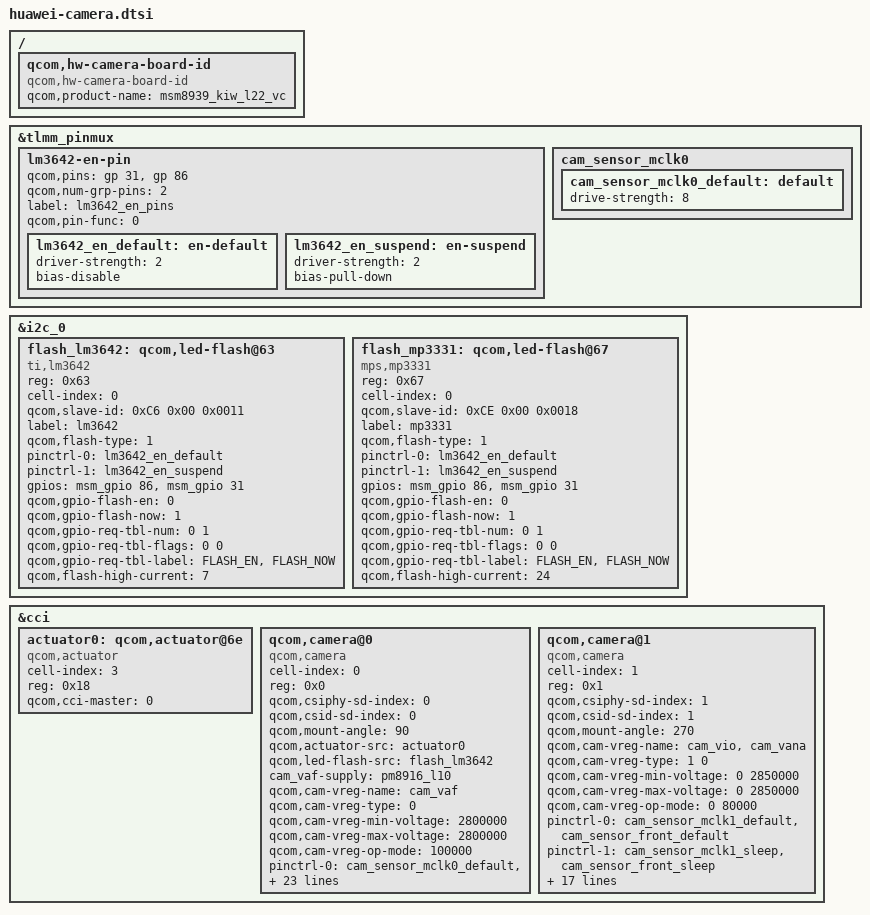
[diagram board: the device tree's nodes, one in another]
/*
 * Copyright (c) 2014, The Linux Foundation. All rights reserved.
 *
 * This program is free software; you can redistribute it and/or modify
 * it under the terms of the GNU General Public License version 2 and
 * only version 2 as published by the Free Software Foundation.
 *
 * This program is distributed in the hope that it will be useful,
 * but WITHOUT ANY WARRANTY; without even the implied warranty of
 * MERCHANTABILITY or FITNESS FOR A PARTICULAR PURPOSE.  See the
 * GNU General Public License for more details.
 */
&tlmm_pinmux {
	lm3642-en-pin {
		qcom,pins = <&gp 31>, <&gp 86>;
		qcom,num-grp-pins = <2>;
		label = "lm3642_en_pins";
		qcom,pin-func = <0>;

		lm3642_en_default: en-default {
			driver-strength = <2>;
			bias-disable;
		};
		lm3642_en_suspend: en-suspend {
			driver-strength = <2>;
			bias-pull-down;
		};
	};
	cam_sensor_mclk0 {
		cam_sensor_mclk0_default: default {
			drive-strength = <8>; /* 8 MA */
		};
	};
};

&i2c_0 { /* BLSP1 QUP2 */
	flash_lm3642:qcom,led-flash@63 {
		reg = <0x63>;
		cell-index = <0>;
		qcom,slave-id = <0xC6 0x00 0x0011>;
		compatible = "ti,lm3642";
		label = "lm3642";
		qcom,flash-type = <1>;
		pinctrl-names = "cam_flash_default","cam_flash_suspend";
		pinctrl-0 = <&lm3642_en_default>;
		pinctrl-1 = <&lm3642_en_suspend>;
		gpios = <&msm_gpio 86 0>,
			<&msm_gpio 31 0>;
		qcom,gpio-flash-en = <0>;
		qcom,gpio-flash-now = <1>;
		qcom,gpio-req-tbl-num = <0 1>;
		qcom,gpio-req-tbl-flags = <0 0>;
		qcom,gpio-req-tbl-label = "FLASH_EN",
			"FLASH_NOW";

		qcom,flash-high-current = <7>;/* 750mA */
	};
	flash_mp3331:qcom,led-flash@67 {
		reg = <0x67>;
		cell-index = <0>;
		qcom,slave-id = <0xCE 0x00 0x0018>;
		compatible = "mps,mp3331";
		label = "mp3331";
		qcom,flash-type = <1>;
		pinctrl-names = "cam_flash_default","cam_flash_suspend";
		pinctrl-0 = <&lm3642_en_default>;
		pinctrl-1 = <&lm3642_en_suspend>;
		gpios = <&msm_gpio 86 0>,
			<&msm_gpio 31 0>;
		qcom,gpio-flash-en = <0>;
		qcom,gpio-flash-now = <1>;
		qcom,gpio-req-tbl-num = <0 1>;
		qcom,gpio-req-tbl-flags = <0 0>;
		qcom,gpio-req-tbl-label = "FLASH_EN",
			"FLASH_NOW";

		qcom,flash-high-current = <24>;/* 750mA */
	};
};

/ {
    qcom,hw-camera-board-id {
		compatible = "qcom,hw-camera-board-id";
		qcom,product-name = "msm8939_kiw_l22_vc";
	};
};

&cci {
	actuator0: qcom,actuator@6e {
		cell-index = <3>;
		reg = <0x18>;
		compatible = "qcom,actuator";
		qcom,cci-master = <0>;
	};

	qcom,camera@0 {
		cell-index = <0>;
		compatible = "qcom,camera";
		reg = <0x0>;
		qcom,csiphy-sd-index = <0>;
		qcom,csid-sd-index = <0>;
		qcom,mount-angle = <90>;
		qcom,actuator-src = <&actuator0>;
		qcom,led-flash-src = <&flash_lm3642>;
		cam_vaf-supply = <&pm8916_l10>;
		qcom,cam-vreg-name = "cam_vaf";
		qcom,cam-vreg-type = <0>;
		qcom,cam-vreg-min-voltage = <2800000>;
		qcom,cam-vreg-max-voltage = <2800000>;
		qcom,cam-vreg-op-mode = <100000>;
		pinctrl-names = "cam_default", "cam_suspend";
		pinctrl-0 = <&cam_sensor_mclk0_default &cam_sensor_rear_default>;
		pinctrl-1 = <&cam_sensor_mclk0_sleep &cam_sensor_rear_sleep>;
		gpios = <&msm_gpio 26 0>,
				<&msm_gpio 35 0>,
				<&msm_gpio 121 0>,//core vreg
				<&msm_gpio 110 0>,
				<&msm_gpio 114 0>,
				<&msm_gpio 120 0>,
				<&msm_gpio 105 0>,
				<&msm_gpio 51 0>;
		qcom,gpio-reset = <1>;
		qcom,gpio-vdig = <2>;
		qcom,gpio-vana = <3>;
		qcom,gpio-vio = <4>;
		qcom,gpio-af-pwdm = <5>;
		qcom,gpio-cam-dvdd-sel = <6>;
		qcom,gpio-cam-id = <7>;
		qcom,gpio-req-tbl-num = <0 1 2 3 4 5 6 7>;
		qcom,gpio-req-tbl-flags = <1 0 0 0 0 0 0 1>;
		qcom,gpio-req-tbl-label = "CAMIF_MCLK",
				"CAM_RESET1",
				"CAM_VDIG",
				"CAM_VANA",
				"CAM_VIO",
				"CAM_AF_PWDM",
				"CAM_DVDD_SEL",
				"CAM_CAM_ID";
		qcom,sensor-position = <0>;
		qcom,sensor-mode = <0>;
		qcom,cci-master = <0>;
		status = "ok";
		clocks = <&clock_gcc clk_mclk0_clk_src>,
				<&clock_gcc clk_gcc_camss_mclk0_clk>;
		clock-names = "cam_src_clk", "cam_clk";
	};

	qcom,camera@1 {
		cell-index = <1>;
		compatible = "qcom,camera";
		reg = <0x1>;
		qcom,csiphy-sd-index = <1>;
		qcom,csid-sd-index = <1>;
		qcom,mount-angle = <270>;
		qcom,cam-vreg-name = "cam_vio", "cam_vana";
		qcom,cam-vreg-type = <1 0>;
		qcom,cam-vreg-min-voltage = <0 2850000>;
		qcom,cam-vreg-max-voltage = <0 2850000>;
		qcom,cam-vreg-op-mode = <0 80000>;
		pinctrl-names = "cam_default", "cam_suspend";
		pinctrl-0 = <&cam_sensor_mclk1_default &cam_sensor_front_default>;
		pinctrl-1 = <&cam_sensor_mclk1_sleep &cam_sensor_front_sleep>;
		gpios = <&msm_gpio 27 0>,
				<&msm_gpio 28 0>,
				<&msm_gpio 33 0>,
				<&msm_gpio 114 0>,
				<&msm_gpio 110 0>,
				<&msm_gpio 52 0>;
		qcom,gpio-reset = <1>;
		qcom,gpio-standby = <2>;
		qcom,gpio-vdig = <3>;
		qcom,gpio-vana = <4>;
		qcom,gpio-cam-id = <5>;
		qcom,gpio-req-tbl-num = <0 1 2 3 4 5>;
		qcom,gpio-req-tbl-flags = <1 0 0 0 0 1>;
		qcom,gpio-req-tbl-label = "CAMIF_MCLK",
				"CAM_RESET",
				"CAM_STANDBY",
				"CAM_VDIG",
				"CAM_VANA",
				"CAM_CAM_ID";
		qcom,sensor-position = <1>;
		qcom,sensor-mode = <0>;
		qcom,cci-master = <0>;
		status = "ok";
		clocks = <&clock_gcc clk_mclk1_clk_src>,
				<&clock_gcc clk_gcc_camss_mclk1_clk>;
		clock-names = "cam_src_clk", "cam_clk";
	};
};
